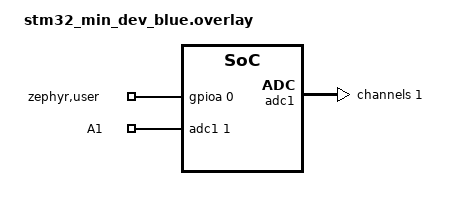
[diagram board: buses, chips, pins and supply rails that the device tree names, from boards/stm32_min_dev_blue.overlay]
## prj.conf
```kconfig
CONFIG_ADC=y

# GPIO
CONFIG_GPIO=y # Ativar o controle dos pinos input e output

# Logging
CONFIG_LOG=y # Log de debug (UART 1)

# 3: info, 0: nada
CONFIG_LOG_DEFAULT_LEVEL=3 
```

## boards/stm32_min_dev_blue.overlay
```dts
/ {
    zephyr,user {
       io-channels = <&adc1 1>; // Canal 1 = Pino A1
       io-channel-names = "A1";
       gpios = <&gpioa 0 GPIO_ACTIVE_HIGH>;	// Pino que controla a base do transistor
    };
};

&adc1 {
	#address-cells = <1>;
	#size-cells = <0>;

	channel@0 {
		reg = <1>;	// Este valor deve ser alterado junto com o pino
		zephyr,gain = "ADC_GAIN_1";
		zephyr,reference = "ADC_REF_INTERNAL";
		zephyr,acquisition-time = <ADC_ACQ_TIME_DEFAULT>;
		zephyr,resolution = <12>;
	};
};

/* vim: set filetype=dts : */
```

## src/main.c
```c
// TODO: Ainda falta fazer a parte do transistor

#include "bateria.h"
#include "zephyr/kernel.h"
#include "zephyr/logging/log.h"

LOG_MODULE_REGISTER();

int main(){
  bateria_init();
  int val;
  while (true) {
    val = bateria_read();
    LOG_INF("%d mV", val);
    k_msleep(100);
  }
}
```

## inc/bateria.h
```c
#include <stdint.h>
#ifndef BATERIA_H

/**
 * @file
 * @brief Biblioteca para a utilização de um sensor de tensão.
 *
 * Este arquivo contém as definições e funções necessárias para inicializar 
 * e ler dados do sensor de tensão desenvolvido pela equipe UNICAMP Baja SAE
 *
 * @author Giancarlo Bonvenuto e Matheus Cunha
 */


/**
 * @brief Valor multiplicado ao valor do `bateria_read()` para transformá-lo de
 * max 3.3V para max 12V
 */
static const double calibration_factor = 1;

/**
 * @brief Inicializa o Analog to Digital Converter (ADC), e os pinos do adc e da
 * base do transistor. Deve ser chamado antes de qualquer função dessa biblioteca
 */
int bateria_init();

/**
 * @brief Ativa o transistor, espera alguns milisegundos e em seguida lê os sinal
 * do trimpot que indica a tensão. E por fim desativa o transitor.
 * 
 * @return 
 * - `>= 0`: caso a leitura seja bem-sucedida. O valor é retornado em milivolts
 * - `< 0`: retorna o erro que ocorreu em alguma das funções executadas
 */
uint32_t bateria_read();

#endif // !BATERIA_H
```

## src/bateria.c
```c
#include <bateria.h>

#include <zephyr/device.h>
#include <zephyr/drivers/adc.h>
#include <zephyr/drivers/gpio.h>
#include <zephyr/kernel.h>
#include <zephyr/logging/log.h>

// Esse código foi altamente inspirado no código de sample do zephyr

LOG_MODULE_REGISTER(Bateria);

const struct gpio_dt_spec *transistor =
    &(const struct gpio_dt_spec)GPIO_DT_SPEC_GET(DT_PATH(zephyr_user), gpios);
const struct adc_dt_spec bateria_adc_channel =
    ADC_DT_SPEC_GET_BY_IDX(DT_PATH(zephyr_user), 0);
static uint16_t buf;
static struct adc_sequence sequence = {
    .buffer = &buf,
    /* buffer size in bytes, not number of samples */
    .buffer_size = sizeof(buf),
};

int bateria_init() {
  LOG_INF("Inicializando...");

  int err;
  err = adc_is_ready_dt(&bateria_adc_channel);
  if (err < 0) {
    LOG_ERR("ADC não está pronto");
    return err;
  }

  err = device_is_ready(transistor->port);
  if (err < 0) {
    LOG_ERR("A porta do pino do transistor não está pronta");
    return err;
  }

  err = gpio_pin_configure_dt(transistor, GPIO_OUTPUT);
  if (err < 0) {
    LOG_ERR("Não foi possível configurar o pino do transistor como output (%d)",
            err);
    return err;
  }

  return 0;
}

uint32_t bateria_read() {
  int err;

  // Vamos habilitar o circuito ativando o transistor
  LOG_INF("Ativando o circuito de leitura da bateria");

  err = gpio_pin_set_dt(transistor, 1);
  if (err < 0) {
    LOG_ERR("Não foi possível setar o pino do transistor para 1 (%d)", err);
    return err;
  }

  // Vamos tentar ler direto com um delay de 1ms
  k_msleep(10);

  LOG_INF("Lendo...");

  int32_t val_mv;

  (void)adc_sequence_init_dt(&bateria_adc_channel, &sequence);

  err = adc_read_dt(&bateria_adc_channel, &sequence);
  if (err < 0) {
    LOG_ERR("Não foi possível ler (%d)", err);
    return err;
  }

  if (bateria_adc_channel.channel_cfg.differential) {
    val_mv = (int32_t)((int16_t)buf);
  } else {
    val_mv = (int32_t)buf;
  }

  /* Converte o valor em milivolts*/
  err = adc_raw_to_millivolts_dt(&bateria_adc_channel, &val_mv);
  if (err < 0) {
    LOG_ERR("Não foi possível converter para mV (%d)", err);
    return err;
  }

  // E agora desativamos o transistor
  err = gpio_pin_set_dt(transistor, 0);
  if (err < 0) {
    LOG_ERR("Não foi possível setar o pino do transistor para 0 (%d)", err);
    return err;
  }

  return val_mv*calibration_factor;
}
```
